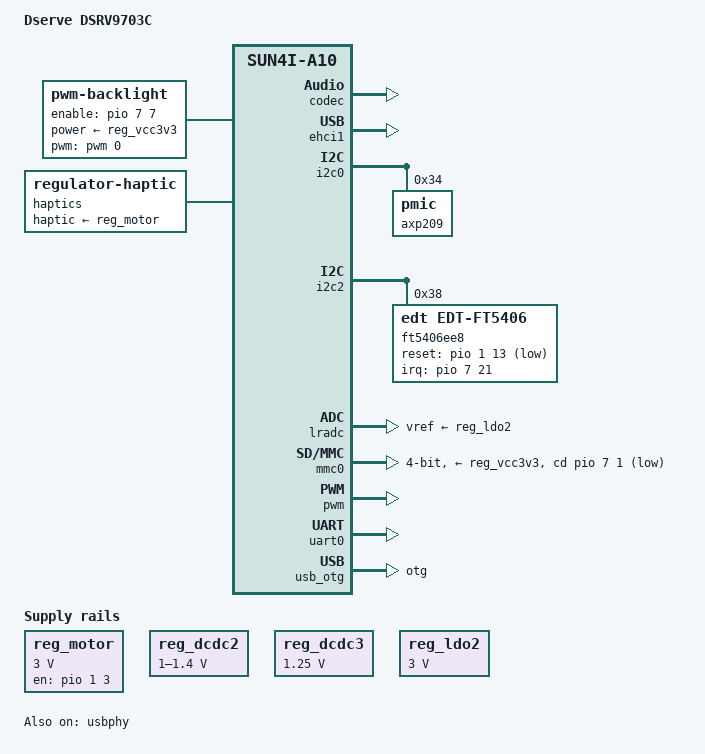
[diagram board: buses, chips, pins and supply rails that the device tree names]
/dts-v1/;
#include "sun4i-a10.dtsi"
#include "sunxi-common-regulators.dtsi"
#include <dt-bindings/gpio/gpio.h>
#include <dt-bindings/input/input.h>
#include <dt-bindings/interrupt-controller/irq.h>
#include <dt-bindings/pwm/pwm.h>
/ {
	model = "Dserve DSRV9703C";
	compatible = "dserve,dsrv9703c", "allwinner,sun4i-a10";
	aliases {
		serial0 = &uart0;
	};
	backlight: backlight {
		compatible = "pwm-backlight";
		pwms = <&pwm 0 50000 PWM_POLARITY_INVERTED>;
		brightness-levels = <0 10 20 30 40 50 60 70 80 90 100>;
		default-brightness-level = <8>;
		enable-gpios = <&pio 7 7 GPIO_ACTIVE_HIGH>;  
		power-supply = <&reg_vcc3v3>;
	};
	chosen {
		stdout-path = "serial0:115200n8";
	};
	haptics {
		compatible = "regulator-haptic";
		haptic-supply = <&reg_motor>;
		min-microvolt = <3000000>;
		max-microvolt = <3000000>;
	};
	reg_motor: reg-motor {
		compatible = "regulator-fixed";
		regulator-name = "vcc-motor";
		regulator-min-microvolt = <3000000>;
		regulator-max-microvolt = <3000000>;
		enable-active-high;
		gpio = <&pio 1 3 GPIO_ACTIVE_HIGH>;  
	};
};
&codec {
	allwinner,pa-gpios = <&pio 7 15 GPIO_ACTIVE_HIGH>;  
	status = "okay";
};
&cpu0 {
	cpu-supply = <&reg_dcdc2>;
};
&ehci1 {
	status = "okay";
};
&i2c0 {
	status = "okay";
	axp209: pmic@34 {
		reg = <0x34>;
		interrupts = <0>;
	};
};
#include "axp209.dtsi"
&i2c1 {
	status = "failed";
};
&i2c2 {
	status = "okay";
	ft5406ee8: touchscreen@38 {
		compatible = "edt,edt-ft5406";
		reg = <0x38>;
		interrupt-parent = <&pio>;
		interrupts = <7 21 IRQ_TYPE_EDGE_FALLING>;
		reset-gpios = <&pio 1 13 GPIO_ACTIVE_LOW>;
		touchscreen-size-x = <1024>;
		touchscreen-size-y = <768>;
	};
};
&lradc {
	vref-supply = <&reg_ldo2>;
	status = "okay";
	button-400 {
		label = "Volume Down";
		linux,code = <KEY_VOLUMEDOWN>;
		channel = <0>;
		voltage = <400000>;
	};
	button-800 {
		label = "Volume Up";
		linux,code = <KEY_VOLUMEUP>;
		channel = <0>;
		voltage = <800000>;
	};
};
&mmc0 {
	vmmc-supply = <&reg_vcc3v3>;
	bus-width = <4>;
	cd-gpios = <&pio 7 1 GPIO_ACTIVE_LOW>;  
	status = "okay";
};
&otg_sram {
	status = "okay";
};
&pwm {
	pinctrl-names = "default";
	pinctrl-0 = <&pwm0_pin>;
	status = "okay";
};
&reg_dcdc2 {
	regulator-always-on;
	regulator-min-microvolt = <1000000>;
	regulator-max-microvolt = <1400000>;
	regulator-name = "vdd-cpu";
};
&reg_dcdc3 {
	regulator-always-on;
	regulator-min-microvolt = <1250000>;
	regulator-max-microvolt = <1250000>;
	regulator-name = "vdd-int-dll";
};
&reg_ldo1 {
	regulator-name = "vdd-rtc";
};
&reg_ldo2 {
	regulator-always-on;
	regulator-min-microvolt = <3000000>;
	regulator-max-microvolt = <3000000>;
	regulator-name = "avcc";
};
&reg_usb0_vbus {
	status = "okay";
};
&reg_usb2_vbus {
	status = "okay";
};
&uart0 {
	pinctrl-names = "default";
	pinctrl-0 = <&uart0_pb_pins>;
	status = "okay";
};
&usb_otg {
	dr_mode = "otg";
	status = "okay";
};
&usbphy {
	usb0_id_det-gpios = <&pio 7 4 (GPIO_ACTIVE_HIGH | GPIO_PULL_UP)>;  
	usb0_vbus_det-gpios = <&pio 7 5 (GPIO_ACTIVE_HIGH | GPIO_PULL_DOWN)>;  
	usb0_vbus-supply = <&reg_usb0_vbus>;
	usb2_vbus-supply = <&reg_usb2_vbus>;
	status = "okay";
};
